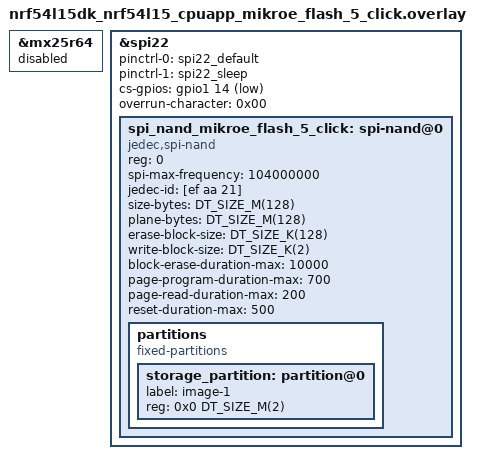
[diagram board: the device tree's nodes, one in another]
/*
 * Copyright (c) 2026 Nordic Semiconductor ASA
 *
 * SPDX-License-Identifier: Apache-2.0
 */

&mx25r64 {
	status = "disabled";
};

/delete-node/ &storage_partition;

mikrobus_spi: &spi22 {
	status = "okay";
	pinctrl-0 = <&spi22_default>;
	pinctrl-1 = <&spi22_sleep>;
	pinctrl-names = "default", "sleep";
	cs-gpios = <&gpio1 14 GPIO_ACTIVE_LOW>;
	overrun-character = <0x00>;

	spi_nand_mikroe_flash_5_click: spi-nand@0 {
		compatible = "jedec,spi-nand";
		reg = <0>;
		status = "okay";
		spi-max-frequency = <104000000>;

		/* w25n01gv parameters */
		jedec-id = [ef aa 21];
		size-bytes = <DT_SIZE_M(128)>;
		plane-bytes = <DT_SIZE_M(128)>;
		erase-block-size = <DT_SIZE_K(128)>;
		write-block-size = <DT_SIZE_K(2)>;
		block-erase-duration-max = <10000>;
		page-program-duration-max = <700>;
		page-read-duration-max = <200>;
		reset-duration-max = <500>;

		partitions {
			compatible = "fixed-partitions";
			#address-cells = <1>;
			#size-cells = <1>;

			storage_partition: partition@0 {
				label = "image-1";
				reg = <0x0 DT_SIZE_M(2)>;
			};
		};
	};
};
